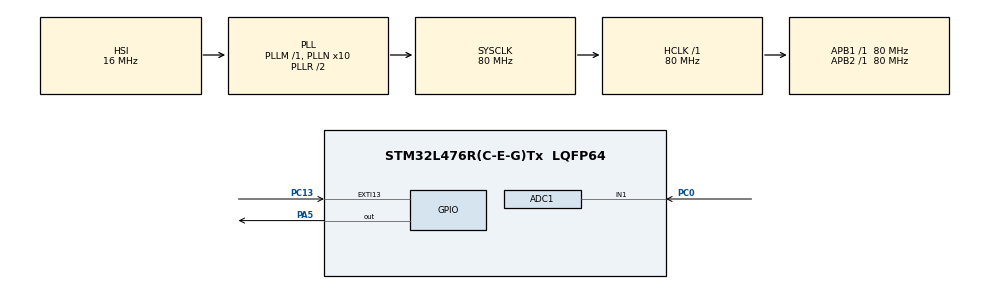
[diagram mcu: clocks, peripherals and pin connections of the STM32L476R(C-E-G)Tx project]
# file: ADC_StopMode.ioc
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ADC1.Channel-1\#ChannelRegularConversion=ADC_CHANNEL_1
ADC1.NbrOfConversionFlag=1
ADC1.OffsetNumber-1\#ChannelRegularConversion=ADC_OFFSET_NONE
ADC1.Rank-1\#ChannelRegularConversion=1
ADC1.Resolution=ADC_RESOLUTION_12B
ADC1.SamplingTime-1\#ChannelRegularConversion=ADC_SAMPLETIME_12CYCLES_5
ADC1.master=1
Mcu.Family=STM32L4
Mcu.Name=STM32L476R(C-E-G)Tx
Mcu.Package=LQFP64
NVIC.EXTI15_10_IRQn=true\:0\:0\:false\:false\:true\:true\:true\:true
NVIC.PriorityGroup=NVIC_PRIORITYGROUP_4
PA13\ (JTMS-SWDIO).Mode=Serial_Wire
PA13\ (JTMS-SWDIO).Signal=SYS_JTMS-SWDIO
PA14\ (JTCK-SWCLK).Mode=Serial_Wire
PA14\ (JTCK-SWCLK).Signal=SYS_JTCK-SWCLK
PA5.PinState=GPIO_PIN_RESET
PA5.Signal=GPIO_Output
PC0.Signal=ADCx_IN1
PC13.GPIO_ModeDefaultEXTI=GPIO_MODE_IT_RISING
PC13.Signal=GPXTI13
ProjectManager.HeapSize=0x200
ProjectManager.StackSize=0x400
ProjectManager.TargetToolchain=STM32CubeIDE
RCC.ADCCLockSelection=RCC_ADCCLKSOURCE_PLLSAI2
RCC.ADCFreq_Value=20000000
RCC.AHBFreq_Value=80000000
RCC.APB1Freq_Value=80000000
RCC.APB1TimFreq_Value=80000000
RCC.APB2Freq_Value=80000000
RCC.APB2TimFreq_Value=80000000
RCC.CortexFreq_Value=80000000
RCC.HCLKFreq_Value=80000000
RCC.HSE_VALUE=8000000
RCC.HSI_VALUE=16000000
RCC.LSE_VALUE=32768
RCC.MSI_VALUE=4000000
RCC.PLLN=10
RCC.PLLSAI1N=10
RCC.PLLSAI1R=RCC_PLLR_DIV8
RCC.PLLSAI2N=10
RCC.PLLSAI2R=RCC_PLLR_DIV8
RCC.PLLSourceVirtual=RCC_PLLSOURCE_HSI
RCC.SYSCLKFreq_VALUE=80000000
RCC.SYSCLKSource=RCC_SYSCLKSOURCE_PLLCLK
RCC.USBFreq_Value=80000000
RCC.VCOOutputFreq_Value=160000000
SH.ADCx_IN1.0=ADC1_IN1,IN1-Single-Ended
board=custom

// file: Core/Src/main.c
/* USER CODE BEGIN Header */
/**
  ******************************************************************************
  * @file           : main.c
  * @brief          : Main program body
  ******************************************************************************
  * @attention
  *
  * Copyright (c) 2023 STMicroelectronics.
  * All rights reserved.
  *
  * This software is licensed under terms that can be found in the LICENSE file
  * in the root directory of this software component.
  * If no LICENSE file comes with this software, it is provided AS-IS.
  *
  ******************************************************************************
  */
/* USER CODE END Header */
#include "main.h"

ADC_HandleTypeDef hadc1;

/* USER CODE BEGIN PV */
uint32_t i;
uint32_t j;
uint32_t adc_value;

/* USER CODE END PV */

void SystemClock_Config(void);
static void MX_GPIO_Init(void);
static void MX_ADC1_Init(void);
/* USER CODE BEGIN PFP */
void HAL_GPIO_EXTI_Callback(uint16_t GPIO_Pin)
  {
    if(GPIO_Pin == GPIO_PIN_13)
    {
  	  SystemClock_Config ();
  	  HAL_ResumeTick();
  	  HAL_PWR_DisableSleepOnExit();
    }
  }
void Read_ADC()
  {
	  HAL_ADC_Start(&hadc1);
      if (HAL_ADC_PollForConversion(&hadc1, 10) == HAL_OK)
      {
    	  adc_value = HAL_ADC_GetValue(&hadc1);
    	  HAL_ADC_Stop(&hadc1);
      }
  }

/* USER CODE END PFP */

int main(void)
{

  /* MCU Configuration--------------------------------------------------------*/

  /* Reset of all peripherals, Initializes the Flash interface and the Systick. */
  HAL_Init();

  /* Configure the system clock */
  SystemClock_Config();

  /* Initialize all configured peripherals */
  MX_GPIO_Init();
  MX_ADC1_Init();
  /* USER CODE BEGIN 2 */
  for (j = 0; j < 4; j++)
   {
     HAL_GPIO_WritePin(GPIOA, GPIO_PIN_5, GPIO_PIN_SET);
     HAL_Delay(1000);
     HAL_GPIO_WritePin(GPIOA, GPIO_PIN_5, GPIO_PIN_RESET);
     HAL_Delay(1000);
   }

  /* USER CODE END 2 */

  /* Infinite loop */
  while (1)
  {

    /* USER CODE BEGIN 3 */
	  	  	  	  HAL_Delay(5000);
	  	  	  	  HAL_SuspendTick();
	  	    	  HAL_PWR_EnableSleepOnExit();
	  	    	  HAL_PWR_EnterSTOPMode(PWR_LOWPOWERREGULATOR_ON, PWR_STOPENTRY_WFE);
	  	    	  for (i = 0; i < 2; i++)
	  	    	   	    {
	  	    	   	      HAL_GPIO_WritePin(GPIOA, GPIO_PIN_5, GPIO_PIN_SET);
	  	    	   	      HAL_Delay(500);
	  	    	   	      HAL_GPIO_WritePin(GPIOA, GPIO_PIN_5, GPIO_PIN_RESET);
	  	    	   	      HAL_Delay(500);
	  	    	   	      }
  }  	                 Read_ADC();
  /* USER CODE END 3 */
}

void SystemClock_Config(void)
{
  RCC_OscInitTypeDef RCC_OscInitStruct = {0};
  RCC_ClkInitTypeDef RCC_ClkInitStruct = {0};

  /** Configure the main internal regulator output voltage
  */
  if (HAL_PWREx_ControlVoltageScaling(PWR_REGULATOR_VOLTAGE_SCALE1) != HAL_OK)
  {
    Error_Handler();
  }

  /** Initializes the RCC Oscillators according to the specified parameters
  * in the RCC_OscInitTypeDef structure.
  */
  RCC_OscInitStruct.OscillatorType = RCC_OSCILLATORTYPE_HSI;
  RCC_OscInitStruct.HSIState = RCC_HSI_ON;
  RCC_OscInitStruct.HSICalibrationValue = RCC_HSICALIBRATION_DEFAULT;
  RCC_OscInitStruct.PLL.PLLState = RCC_PLL_ON;
  RCC_OscInitStruct.PLL.PLLSource = RCC_PLLSOURCE_HSI;
  RCC_OscInitStruct.PLL.PLLM = 1;
  RCC_OscInitStruct.PLL.PLLN = 10;
  RCC_OscInitStruct.PLL.PLLP = RCC_PLLP_DIV7;
  RCC_OscInitStruct.PLL.PLLQ = RCC_PLLQ_DIV2;
  RCC_OscInitStruct.PLL.PLLR = RCC_PLLR_DIV2;
  if (HAL_RCC_OscConfig(&RCC_OscInitStruct) != HAL_OK)
  {
    Error_Handler();
  }

  /** Initializes the CPU, AHB and APB buses clocks
  */
  RCC_ClkInitStruct.ClockType = RCC_CLOCKTYPE_HCLK|RCC_CLOCKTYPE_SYSCLK
                              |RCC_CLOCKTYPE_PCLK1|RCC_CLOCKTYPE_PCLK2;
  RCC_ClkInitStruct.SYSCLKSource = RCC_SYSCLKSOURCE_PLLCLK;
  RCC_ClkInitStruct.AHBCLKDivider = RCC_SYSCLK_DIV1;
  RCC_ClkInitStruct.APB1CLKDivider = RCC_HCLK_DIV1;
  RCC_ClkInitStruct.APB2CLKDivider = RCC_HCLK_DIV1;

  if (HAL_RCC_ClockConfig(&RCC_ClkInitStruct, FLASH_LATENCY_4) != HAL_OK)
  {
    Error_Handler();
  }
}

static void MX_ADC1_Init(void)
{

  ADC_MultiModeTypeDef multimode = {0};
  ADC_ChannelConfTypeDef sConfig = {0};

  /** Common config
  */
  hadc1.Instance = ADC1;
  hadc1.Init.ClockPrescaler = ADC_CLOCK_ASYNC_DIV1;
  hadc1.Init.Resolution = ADC_RESOLUTION_12B;
  hadc1.Init.DataAlign = ADC_DATAALIGN_RIGHT;
  hadc1.Init.ScanConvMode = ADC_SCAN_DISABLE;
  hadc1.Init.EOCSelection = ADC_EOC_SINGLE_CONV;
  hadc1.Init.LowPowerAutoWait = DISABLE;
  hadc1.Init.ContinuousConvMode = DISABLE;
  hadc1.Init.NbrOfConversion = 1;
  hadc1.Init.DiscontinuousConvMode = DISABLE;
  hadc1.Init.ExternalTrigConv = ADC_SOFTWARE_START;
  hadc1.Init.ExternalTrigConvEdge = ADC_EXTERNALTRIGCONVEDGE_NONE;
  hadc1.Init.DMAContinuousRequests = DISABLE;
  hadc1.Init.Overrun = ADC_OVR_DATA_PRESERVED;
  hadc1.Init.OversamplingMode = DISABLE;
  if (HAL_ADC_Init(&hadc1) != HAL_OK)
  {
    Error_Handler();
  }

  /** Configure the ADC multi-mode
  */
  multimode.Mode = ADC_MODE_INDEPENDENT;
  if (HAL_ADCEx_MultiModeConfigChannel(&hadc1, &multimode) != HAL_OK)
  {
    Error_Handler();
  }

  /** Configure Regular Channel
  */
  sConfig.Channel = ADC_CHANNEL_1;
  sConfig.Rank = ADC_REGULAR_RANK_1;
  sConfig.SamplingTime = ADC_SAMPLETIME_12CYCLES_5;
  sConfig.SingleDiff = ADC_SINGLE_ENDED;
  sConfig.OffsetNumber = ADC_OFFSET_NONE;
  sConfig.Offset = 0;
  if (HAL_ADC_ConfigChannel(&hadc1, &sConfig) != HAL_OK)
  {
    Error_Handler();
  }

}

static void MX_GPIO_Init(void)
{
  GPIO_InitTypeDef GPIO_InitStruct = {0};

  /* GPIO Ports Clock Enable */
  __HAL_RCC_GPIOC_CLK_ENABLE();
  __HAL_RCC_GPIOA_CLK_ENABLE();

  /*Configure GPIO pin Output Level */
  HAL_GPIO_WritePin(GPIOA, GPIO_PIN_5, GPIO_PIN_RESET);

  /*Configure GPIO pin : PC13 */
  GPIO_InitStruct.Pin = GPIO_PIN_13;
  GPIO_InitStruct.Mode = GPIO_MODE_IT_RISING;
  GPIO_InitStruct.Pull = GPIO_NOPULL;
  HAL_GPIO_Init(GPIOC, &GPIO_InitStruct);

  /*Configure GPIO pin : PA5 */
  GPIO_InitStruct.Pin = GPIO_PIN_5;
  GPIO_InitStruct.Mode = GPIO_MODE_OUTPUT_PP;
  GPIO_InitStruct.Pull = GPIO_NOPULL;
  GPIO_InitStruct.Speed = GPIO_SPEED_FREQ_LOW;
  HAL_GPIO_Init(GPIOA, &GPIO_InitStruct);

  /* EXTI interrupt init*/
  HAL_NVIC_SetPriority(EXTI15_10_IRQn, 0, 0);
  HAL_NVIC_EnableIRQ(EXTI15_10_IRQn);

}

void Error_Handler(void)
{
  __disable_irq();
  while (1)
  {
  }
}
